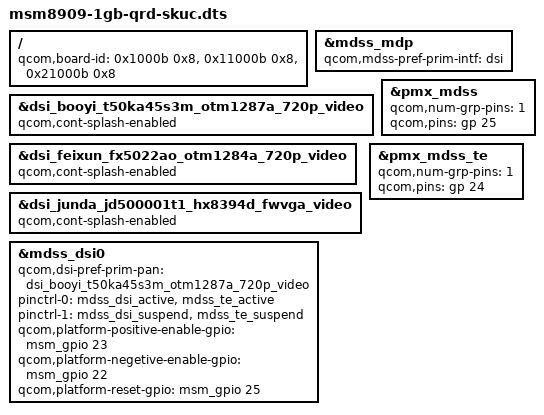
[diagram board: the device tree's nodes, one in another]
/* Copyright (c) 2014, The Linux Foundation. All rights reserved.
 *
 * This program is free software; you can redistribute it and/or modify
 * it under the terms of the GNU General Public License version 2 and
 * only version 2 as published by the Free Software Foundation.
 *
 * This program is distributed in the hope that it will be useful,
 * but WITHOUT ANY WARRANTY; without even the implied warranty of
 * MERCHANTABILITY or FITNESS FOR A PARTICULAR PURPOSE.  See the
 * GNU General Public License for more details.
 */
/* =======================================================================
 *
 * when        	who         	why                           		comment tag
 *
 * ----------	---------	-------------------------------------	--------------------------
 * 2015-06-03	yaming.chen	LCM external power supply		FEIXUN_LCM_EXTERNAL_POWER_SUPPLY_CHENYAMING_001
 *
 */

/dts-v1/;

#include "msm8909-qrd-skuc.dtsi"
#include "e653lw-dsi-panel-booyi-t50ka45s3m-otm1287a-720p-video.dtsi"
#include "e653lw-dsi-panel-feixun-fx5022ao-otm1284a-720p-video.dtsi"
#include "e653lw-dsi-panel-junda-jd500001t1-hx8394d-720p-video.dtsi"

/ {
	qcom,board-id= <0x1000b 0x8>, <0x11000b 0x8>, <0x21000b 0x8>;
};

&mdss_mdp {
	qcom,mdss-pref-prim-intf = "dsi";
};

&dsi_booyi_t50ka45s3m_otm1287a_720p_video {
	qcom,cont-splash-enabled;
};

&dsi_feixun_fx5022ao_otm1284a_720p_video {
	qcom,cont-splash-enabled;
};

&dsi_junda_jd500001t1_hx8394d_fwvga_video{
	qcom,cont-splash-enabled;
};

&pmx_mdss {
	qcom,num-grp-pins = <1>;
	qcom,pins = <&gp 25>;
};

&pmx_mdss_te {
	qcom,num-grp-pins = <1>;
	qcom,pins = <&gp 24>;
};

&mdss_dsi0 {
	qcom,dsi-pref-prim-pan = <&dsi_booyi_t50ka45s3m_otm1287a_720p_video>;
	pinctrl-names = "mdss_default", "mdss_sleep";
	pinctrl-0 = <&mdss_dsi_active &mdss_te_active>;
	pinctrl-1 = <&mdss_dsi_suspend &mdss_te_suspend>;

       // FEIXUN_LCM_EXTERNAL_POWER_SUPPLY_CHENYAMING_001 START
       qcom,platform-positive-enable-gpio = <&msm_gpio 23 0>;
       qcom,platform-negetive-enable-gpio = <&msm_gpio 22 0>;
       // FEIXUN_LCM_EXTERNAL_POWER_SUPPLY_CHENYAMING_001 END
	qcom,platform-reset-gpio = <&msm_gpio 25 0>;
};
